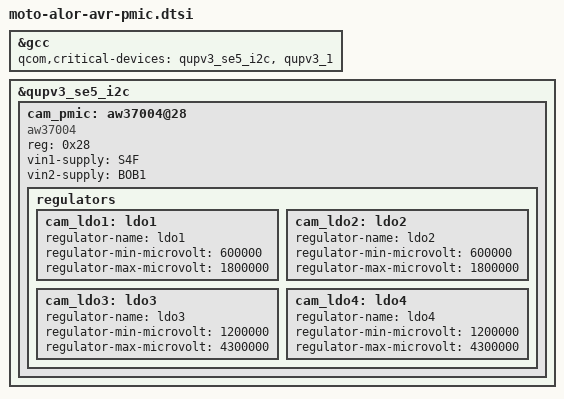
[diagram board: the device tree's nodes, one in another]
/*
 * Each QUP device that's a parent to PMIC must be listed as a critical device
 * to GCC.
 */

&gcc {
	qcom,critical-devices = <&qupv3_se5_i2c>, <&qupv3_1>;
};

&qupv3_se5_i2c {
	status = "ok";
	cam_pmic: aw37004@28 {
		compatible = "aw37004";
		reg = <0x28>;

		vin1-supply = <&S4F>;
		vin2-supply = <&BOB1>;

		regulators {
			cam_ldo1: ldo1 {
				regulator-name = "ldo1";
				regulator-min-microvolt = <600000>;
				regulator-max-microvolt = <1800000>;
			};

			cam_ldo2: ldo2 {
				regulator-name = "ldo2";
				regulator-min-microvolt = <600000>;
				regulator-max-microvolt = <1800000>;
			};

			cam_ldo3: ldo3 {
				regulator-name = "ldo3";
				regulator-min-microvolt = <1200000>;
				regulator-max-microvolt = <4300000>;
			};

			cam_ldo4: ldo4 {
				regulator-name = "ldo4";
				regulator-min-microvolt = <1200000>;
				regulator-max-microvolt = <4300000>;
			};
		};
	};
};
